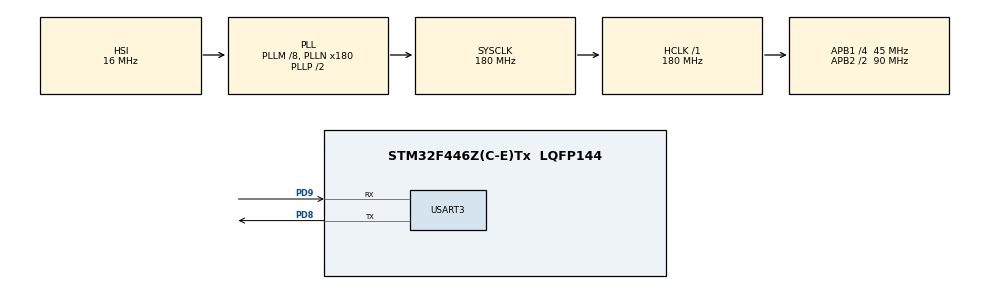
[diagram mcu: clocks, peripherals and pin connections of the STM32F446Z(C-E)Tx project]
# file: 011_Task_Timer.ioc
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FREERTOS.BinarySemaphores01=myBinarySem01,Dynamic,NULL,Depleted
FREERTOS.Tasks01=Task01,32,128,StartTask,Default,NULL,Dynamic,NULL,NULL;Task02,24,128,StartTask02,Default,NULL,Dynamic,NULL,NULL
FREERTOS.Timers01=myTimer01,Callback01,osTimerPeriodic,Default,NULL,Dynamic,NULL
FREERTOS.configUSE_NEWLIB_REENTRANT=1
Mcu.Family=STM32F4
Mcu.Name=STM32F446Z(C-E)Tx
Mcu.Package=LQFP144
NVIC.PriorityGroup=NVIC_PRIORITYGROUP_4
NVIC.TIM6_DAC_IRQn=true\:15\:0\:false\:false\:true\:false\:false\:true\:true
NVIC.TimeBase=TIM6_DAC_IRQn
NVIC.TimeBaseIP=TIM6
PD8.Mode=Asynchronous
PD8.Signal=USART3_TX
PD9.Mode=Asynchronous
PD9.Signal=USART3_RX
ProjectManager.HeapSize=0x200
ProjectManager.StackSize=0x400
ProjectManager.TargetToolchain=STM32CubeIDE
RCC.48MHZClocksFreq_Value=24000000
RCC.AHBFreq_Value=180000000
RCC.APB1CLKDivider=RCC_HCLK_DIV4
RCC.APB1Freq_Value=45000000
RCC.APB1TimFreq_Value=90000000
RCC.APB2CLKDivider=RCC_HCLK_DIV2
RCC.APB2Freq_Value=90000000
RCC.APB2TimFreq_Value=180000000
RCC.CortexFreq_Value=180000000
RCC.HCLKFreq_Value=180000000
RCC.HSE_VALUE=8000000
RCC.HSI_VALUE=16000000
RCC.PLLM=8
RCC.PLLMUL=RCC_PLL_MUL9
RCC.PLLN=180
RCC.PLLQ=7
RCC.PRESCALERUSB=RCC_USBCLKSOURCE_PLL_DIV1_5
RCC.SYSCLKFreq_VALUE=180000000
RCC.SYSCLKSource=RCC_SYSCLKSOURCE_PLLCLK
RCC.SYSCLKSourceVirtual=RCC_SYSCLKSOURCE_PLLCLK
RCC.USBFreq_Value=51428571.428571425
RCC.VCOOutputFreq_Value=360000000
USART3.VirtualMode=VM_ASYNC
VP_FREERTOS_VS_CMSIS_V2.Mode=CMSIS_V2
VP_SYS_VS_tim6.Mode=TIM6
board=NUCLEO-F446ZE

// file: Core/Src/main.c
/* USER CODE BEGIN Header */
/**
  ******************************************************************************
  * @file           : main.c
  * @brief          : Main program body
  ******************************************************************************
  * @attention
  *
  * Copyright (c) 2026 STMicroelectronics.
  * All rights reserved.
  *
  * This software is licensed under terms that can be found in the LICENSE file
  * in the root directory of this software component.
  * If no LICENSE file comes with this software, it is provided AS-IS.
  *
  ******************************************************************************
  */
/* USER CODE END Header */
#include "main.h"
#include "cmsis_os.h"

/* USER CODE BEGIN Includes */
#include<stdio.h>
#include<string.h>
/* USER CODE END Includes */

UART_HandleTypeDef huart3;

/* Definitions for Task01 */
osThreadId_t Task01Handle;
const osThreadAttr_t Task01_attributes = {
  .name = "Task01",
  .stack_size = 128 * 4,
  .priority = (osPriority_t) osPriorityAboveNormal,
};
/* Definitions for Task02 */
osThreadId_t Task02Handle;
const osThreadAttr_t Task02_attributes = {
  .name = "Task02",
  .stack_size = 128 * 4,
  .priority = (osPriority_t) osPriorityNormal,
};
/* Definitions for myTimer01 */
osTimerId_t myTimer01Handle;
const osTimerAttr_t myTimer01_attributes = {
  .name = "myTimer01"
};
/* Definitions for myBinarySem01 */
osSemaphoreId_t myBinarySem01Handle;
const osSemaphoreAttr_t myBinarySem01_attributes = {
  .name = "myBinarySem01"
};

void SystemClock_Config(void);
static void MX_GPIO_Init(void);
static void MX_USART3_UART_Init(void);
void StartTask(void *argument);
void StartTask02(void *argument);
void Callback01(void *argument);

int main(void)
{

  /* MCU Configuration--------------------------------------------------------*/

  /* Reset of all peripherals, Initializes the Flash interface and the Systick. */
  HAL_Init();

  /* Configure the system clock */
  SystemClock_Config();

  /* Initialize all configured peripherals */
  MX_GPIO_Init();
  MX_USART3_UART_Init();

  /* Init scheduler */
  osKernelInitialize();

  /* Create the semaphores(s) */
  /* creation of myBinarySem01 */
  myBinarySem01Handle = osSemaphoreNew(1, 0, &myBinarySem01_attributes);

  /* Create the timer(s) */
  /* creation of myTimer01 */
  myTimer01Handle = osTimerNew(Callback01, osTimerPeriodic, NULL, &myTimer01_attributes);

  /* USER CODE BEGIN RTOS_TIMERS */
  /* start timers, add new ones, ... */
  osTimerStart(myTimer01Handle, 1000);
  /* USER CODE END RTOS_TIMERS */

  /* Create the thread(s) */
  /* creation of Task01 */
  Task01Handle = osThreadNew(StartTask, NULL, &Task01_attributes);

  /* creation of Task02 */
  Task02Handle = osThreadNew(StartTask02, NULL, &Task02_attributes);

  /* Start scheduler */
  osKernelStart();

  /* We should never get here as control is now taken by the scheduler */

  /* Infinite loop */
  while (1)
  {

  }
}

void SystemClock_Config(void)
{
  RCC_OscInitTypeDef RCC_OscInitStruct = {0};
  RCC_ClkInitTypeDef RCC_ClkInitStruct = {0};

  /** Configure the main internal regulator output voltage
  */
  __HAL_RCC_PWR_CLK_ENABLE();
  __HAL_PWR_VOLTAGESCALING_CONFIG(PWR_REGULATOR_VOLTAGE_SCALE1);

  /** Initializes the RCC Oscillators according to the specified parameters
  * in the RCC_OscInitTypeDef structure.
  */
  RCC_OscInitStruct.OscillatorType = RCC_OSCILLATORTYPE_HSI;
  RCC_OscInitStruct.HSIState = RCC_HSI_ON;
  RCC_OscInitStruct.HSICalibrationValue = RCC_HSICALIBRATION_DEFAULT;
  RCC_OscInitStruct.PLL.PLLState = RCC_PLL_ON;
  RCC_OscInitStruct.PLL.PLLSource = RCC_PLLSOURCE_HSI;
  RCC_OscInitStruct.PLL.PLLM = 8;
  RCC_OscInitStruct.PLL.PLLN = 180;
  RCC_OscInitStruct.PLL.PLLP = RCC_PLLP_DIV2;
  RCC_OscInitStruct.PLL.PLLQ = 7;
  RCC_OscInitStruct.PLL.PLLR = 2;
  if (HAL_RCC_OscConfig(&RCC_OscInitStruct) != HAL_OK)
  {
    Error_Handler();
  }

  /** Activate the Over-Drive mode
  */
  if (HAL_PWREx_EnableOverDrive() != HAL_OK)
  {
    Error_Handler();
  }

  /** Initializes the CPU, AHB and APB buses clocks
  */
  RCC_ClkInitStruct.ClockType = RCC_CLOCKTYPE_HCLK|RCC_CLOCKTYPE_SYSCLK
                              |RCC_CLOCKTYPE_PCLK1|RCC_CLOCKTYPE_PCLK2;
  RCC_ClkInitStruct.SYSCLKSource = RCC_SYSCLKSOURCE_PLLCLK;
  RCC_ClkInitStruct.AHBCLKDivider = RCC_SYSCLK_DIV1;
  RCC_ClkInitStruct.APB1CLKDivider = RCC_HCLK_DIV4;
  RCC_ClkInitStruct.APB2CLKDivider = RCC_HCLK_DIV2;

  if (HAL_RCC_ClockConfig(&RCC_ClkInitStruct, FLASH_LATENCY_5) != HAL_OK)
  {
    Error_Handler();
  }
}

static void MX_USART3_UART_Init(void)
{

  huart3.Instance = USART3;
  huart3.Init.BaudRate = 115200;
  huart3.Init.WordLength = UART_WORDLENGTH_8B;
  huart3.Init.StopBits = UART_STOPBITS_1;
  huart3.Init.Parity = UART_PARITY_NONE;
  huart3.Init.Mode = UART_MODE_TX_RX;
  huart3.Init.HwFlowCtl = UART_HWCONTROL_NONE;
  huart3.Init.OverSampling = UART_OVERSAMPLING_16;
  if (HAL_UART_Init(&huart3) != HAL_OK)
  {
    Error_Handler();
  }

}

static void MX_GPIO_Init(void)
{

  /* GPIO Ports Clock Enable */
  __HAL_RCC_GPIOD_CLK_ENABLE();

}

void StartTask(void *argument)
{
  /* USER CODE BEGIN 5 */
	char msg[]="Task Woken up\r\n";
  /* Infinite loop */
  for(;;)
  {
	osSemaphoreAcquire(myBinarySem01Handle, osWaitForever);
	HAL_UART_Transmit(&huart3, (uint8_t*)msg,strlen(msg),HAL_MAX_DELAY);
  }
  /* USER CODE END 5 */
}

void StartTask02(void *argument)
{
  /* USER CODE BEGIN StartTask02 */
	char msg[]="This is Task 02\r\n";
  /* Infinite loop */
  for(;;)
  {
	  HAL_UART_Transmit(&huart3, (uint8_t*)msg,strlen(msg),HAL_MAX_DELAY);
  }
  /* USER CODE END StartTask02 */
}

/* Callback01 function */
void Callback01(void *argument)
{
  /* USER CODE BEGIN Callback01 */
	osSemaphoreRelease(myBinarySem01Handle);
  /* USER CODE END Callback01 */
}

void HAL_TIM_PeriodElapsedCallback(TIM_HandleTypeDef *htim)
{
  if (htim->Instance == TIM6)
  {
    HAL_IncTick();
  }
}

void Error_Handler(void)
{
  __disable_irq();
  while (1)
  {
  }
}
